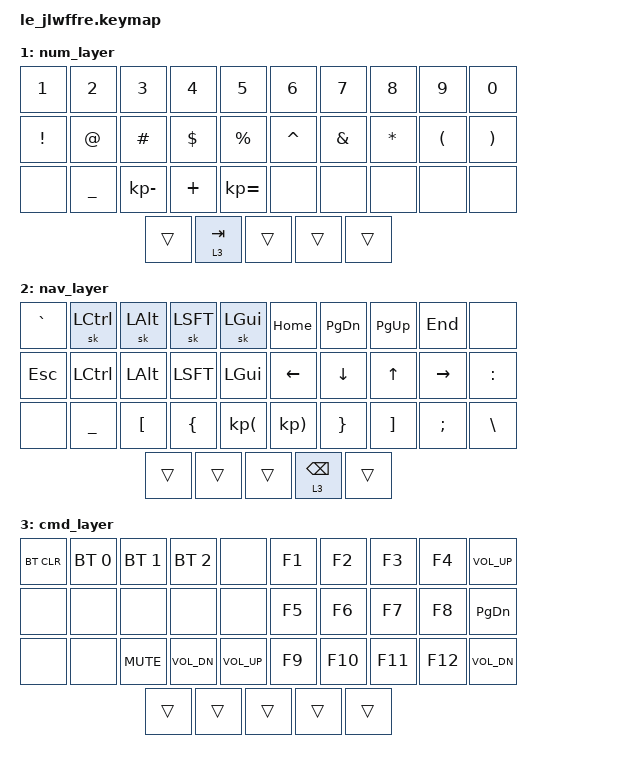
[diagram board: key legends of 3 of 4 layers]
/*
 * Copyright (c) 2022 The ZMK Contributors
 *
 * SPDX-License-Identifier: MIT
 */

#include <behaviors.dtsi>
#include <dt-bindings/zmk/keys.h>
#include <dt-bindings/zmk/bt.h>

// Home row mods macro
#define HRML(k1,k2,k3,k4) &ht LCTRL k1 &ht LALT  k2 &ht LSHFT k3  &ht LGUI  k4
#define HRMR(k1,k2,k3,k4) &ht RGUI  k1 &ht RSHFT k2 &ht RALT  k3  &ht RCTRL k4

/ {
    behaviors {
        ht: hold_tap {
            compatible = "zmk,behavior-hold-tap";
            #binding-cells = <2>;
            flavor = "balanced";
            tapping-term-ms = <200>;
            quick-tap-ms = <220>;
            require-prior-idle-ms = <125>;
            bindings = <&kp>, <&kp>;
        };
        mt: mod_tap {
            #binding-cells = <2>;
            tapping-term-ms = <200>;
            quick-tap-ms = <220>;
            require-prior-idle-ms = <125>;
            bindings = <&kp>, <&kp>;
        };
        as_ht: autoshift_hold_tap {
            compatible = "zmk,behavior-hold-tap";
            #binding-cells = <2>;
            tapping-term-ms = <200>;
            bindings = <&shifted>, <&kp>;
            flavor = "tap-preferred";
        };

        combos {
            compatible = "zmk,combos";
            combo_esc {
                timeout-ms = <50>;
                key-positions = <0 1>;
                bindings = <&kp ESC>;
            };
            combo_del {
                timeout-ms = <50>;
                key-positions = <8 9>;
                bindings = <&kp DEL>;
            };
            combo_reset {
                timeout-ms = <50>;
                key-positions = <0 9>;
                layers = <2>;
                bindings = <&sys_reset>;
            };
            combo_boot {
                timeout-ms = <50>;
                key-positions = <5 20>;
                layers = <2>;
                bindings = <&bootloader>;
            };
        };
    };

    macros {
        shifted: macro_shifted_kp {
            #binding-cells = <1>;
            compatible = "zmk,behavior-macro-one-param";
            bindings =
              <&macro_press &kp LSHFT>,
              <&macro_param_1to1 &macro_tap &kp MACRO_PLACEHOLDER>,
              <&macro_release &kp LSHFT>;
        };
        as: autoshift {
            compatible = "zmk,behavior-macro-one-param";
            #binding-cells = <1>;
            bindings =
              <&macro_press>,
              <&macro_param_1to1>,
              <&macro_param_1to2>,
              <&as_ht MACRO_PLACEHOLDER MACRO_PLACEHOLDER>,
              <&macro_pause_for_release>,
              <&macro_release>,
              <&macro_param_1to1>,
              <&macro_param_1to2>,
              <&as_ht MACRO_PLACEHOLDER MACRO_PLACEHOLDER>;
        };
    };

    keymap {
        compatible = "zmk,keymap";
        default_layer {
            bindings = <
        //╭──────────┬──────────┬──────────┬──────────┬──────────╮                      ╭──────────┬──────────┬──────────┬──────────┬──────────╮
        //│  Q       │  W       │  E       │  R       │  T       │                      │  Y       │  U       │  I       │  O       │ P        │
            &kp Q      &kp W      &kp E      &kp R      &kp T                             &kp Y      &kp U      &kp I      &kp O      &kp P
        //├──────────┼──────────┼──────────┼──────────┼──────────┤                      ├──────────┼──────────┼──────────┼──────────┼──────────┤
        //│  A       │  S       │  D       │  F       │  G       │                      │  H       │  J       │  K       │  L       │ '       │
             &kp A     HRML(S,     D,         F,         G)                              HRMR(H,      J,         K,         L)        &kp SQT
        //├──────────┼──────────┼──────────┼──────────┼──────────┤                      ├──────────┼──────────┼──────────┼──────────┼──────────┤
        //│  Z       │  X       │  C       │  V       │  B       │                      │  N       │  M       │ , <      │ . >      │ / ?      │
            &kp Z      &kp X      &kp C      &kp V      &kp B                             &kp N      &kp M      &kp COMMA  &kp DOT    &kp FSLH
        //╰──────────┴──────────┴──────────┼──────────┴──────────┤                      ├──────────┴──────────┼──────────┴──────────┴──────────╯
                                  &lt 3 CAPS       &lt 2 RET          &kp C_MUTE             &lt 1 SPACE       &lt 2 RET
        //                      ╰──────────┼─────────────────────╯                      ╰─────────────────────┼──────────╯
            >;
            sensor-bindings = <&inc_dec_kp C_VOL_UP C_VOL_DN>;
        };

        num_layer {
            bindings = <
        //╭──────────┬──────────┬──────────┬──────────┬──────────╮      ╭──────────┬──────────┬──────────┬──────────┬──────────╮
        //│  1       │     2    │     3    │     4    │     5    │      │  6       │  7       │  8       │  9       │  0       │
            &kp N1     &kp N2      &kp N3      &kp N4    &kp N5           &kp N6    &kp N7      &kp N8     &kp N9   &kp N0
        //├──────────┼──────────┼──────────┼──────────┼──────────┤      ├──────────┼──────────┼──────────┼──────────┼──────────┤
        //│  1 !     │  2 @     │  3 #     │  4 $     │  5 %     │      │  6 ^     │  7 &     │  8 *     │  9 (     │  0 )     │
            &kp EXCL   &kp AT     &kp HASH   &kp DLLR   &kp PRCNT         &kp CARET  &kp AMPS   &kp STAR   &kp LPRN   &kp RPRN
        //├──────────┼──────────┼──────────┼──────────┼──────────┤      ├──────────┼──────────┼──────────┼──────────┼──────────┤
        //│          │          │          │          │          │      │          │          │          │          │          │
            &none     &kp UNDER &kp KP_MINUS &kp PLUS  &kp KP_EQUAL       &none      &none      &none     &none      &none
        //╰──────────┴──────────┴──────────┼──────────┼──────────┤      ├──────────┼──────────┼──────────┴──────────┴──────────╯
                                             &trans     &lt 3 TAB  &trans  &trans     &trans
        //                                 ╰──────────┴──────────╯      ╰──────────┴──────────╯
            >;
            sensor-bindings = <&inc_dec_kp C_VOL_UP C_VOL_DN>;
        };

        nav_layer {
            bindings = <
        //╭──────────┬──────────┬──────────┬──────────┬──────────╮      ╭──────────┬──────────┬──────────┬──────────┬──────────╮
        //│&as GRAVE │          │          │          │          │      │  HOME    │   PG_DN  │   PG_UP  │  END     │          │
            &kp GRAVE  &sk LCTL  &sk LALT   &sk LSFT    &sk LGUI          &kp HOME    &kp PG_DN  &kp PG_UP   &kp END    &none
        //├──────────┼──────────┼──────────┼──────────┼──────────┤      ├──────────┼──────────┼──────────┼──────────┼──────────┤
        //│  ESC     │  LCTL    │  LALT    │  LSFT    │  LGUI    │      │          │          │          │          │  :       │
            &kp ESC     &kp LCTL   &kp LALT   &kp LSFT   &kp LGUI         &kp LEFT   &kp DOWN   &kp UP     &kp RIGHT  &kp COLON
        //├──────────┼──────────┼──────────┼──────────┼──────────┤      ├──────────┼──────────┼──────────┼──────────┼──────────┤
        //│          │     _    │     [    │    { [   │     (    │      │    )     │   }  ]   │     ]    │    ; ;   │    \ |   │
            &none      &kp UNDER   &kp LBKT  &kp LBRC    &kp KP_LPAR     &kp KP_RPAR &kp RBRC   &kp RBKT   &kp SEMI   &kp BSLH
        //╰──────────┴──────────┴──────────┼──────────┼──────────┤      ├──────────┼──────────┼──────────┴──────────┴──────────╯
                                             &trans     &trans    &trans  &lt 3 BKSP  &trans
        //                                 ╰──────────┴──────────╯      ╰──────────┴──────────╯
            >;
            sensor-bindings = <&inc_dec_kp C_VOL_UP C_VOL_DN>;
        };

        cmd_layer {
            bindings = <
        //╭──────────┬──────────┬──────────┬──────────┬──────────╮      ╭──────────┬──────────┬──────────┬──────────┬──────────╮
        //│          │          │          │          │          │      │  F1      │   F2     │  F3      │    F4    │  Vol+    │
            &bt BT_CLR  &bt BT_SEL 0 &bt BT_SEL 1 &bt BT_SEL 2 &none      &kp F1    &kp F2      &kp F3     &kp F4      &kp C_VOL_UP
        //├──────────┼──────────┼──────────┼──────────┼──────────┤      ├──────────┼──────────┼──────────┼──────────┼──────────┤
        //│          │          │          │          │          │      │  F5      │  F6      │  F7      │  F8      │ C_PLAY   │
            &none       &none     &none       &none      &none             &kp F5    &kp F6      &kp F7     &kp F8    &kp PG_DN
        //├──────────┼──────────┼──────────┼──────────┼──────────┤      ├──────────┼──────────┼──────────┼──────────┼──────────┤
        //│          │          │          │          │          │      │  F9      │  F10     │ F11      │ F12      │  Vol-    │
            &none      &none      &kp C_MUTE &kp C_VOL_DN &kp C_VOL_UP    &kp F9      &kp F10   &kp F11    &kp F12    &kp C_VOL_DN
        //╰──────────┴──────────┴──────────┼──────────┼──────────┤      ├──────────┼──────────┼──────────┴──────────┴──────────╯
                                             &trans     &trans    &trans  &trans     &trans
        //                                 ╰──────────┴──────────╯      ╰──────────┴──────────╯
            >;
            sensor-bindings = <&inc_dec_kp C_VOL_UP C_VOL_DN>;
        };

    };

};
